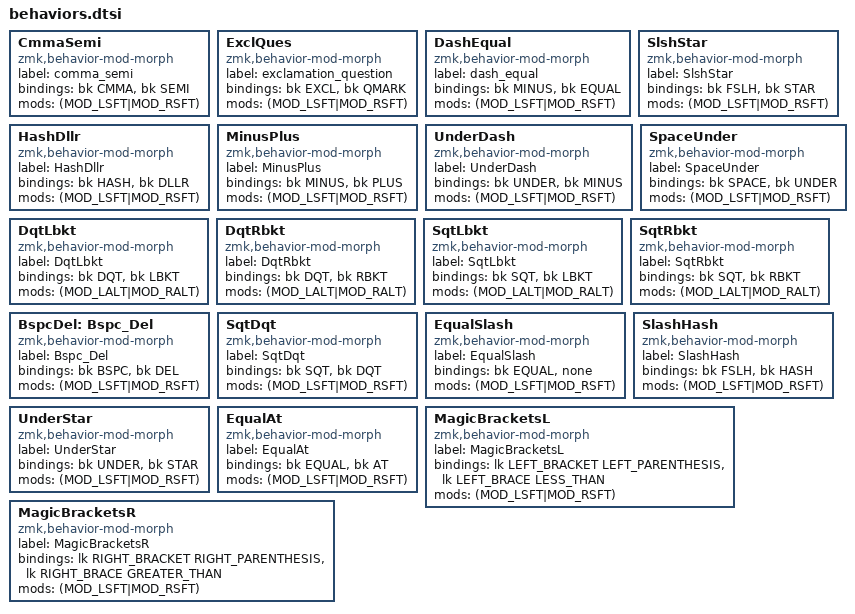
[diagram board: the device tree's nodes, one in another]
CmmaSemi: CmmaSemi {
    compatible = "zmk,behavior-mod-morph";
    label = "comma_semi";
    #binding-cells = <0>;
    bindings = <&bk CMMA>, <&bk SEMI>;
    mods = <(MOD_LSFT|MOD_RSFT)>;
};

ExclQues: ExclQues {
    compatible = "zmk,behavior-mod-morph";
    label = "exclamation_question";
    #binding-cells = <0>;
    bindings = <&bk EXCL>, <&bk QMARK>;
    mods = <(MOD_LSFT|MOD_RSFT)>;
};

DashEqual: DashEqual {
    compatible = "zmk,behavior-mod-morph";
    label = "dash_equal";
    #binding-cells = <0>;
    bindings = <&bk MINUS>, <&bk EQUAL>;
    mods = <(MOD_LSFT|MOD_RSFT)>;
};

SlshStar: SlshStar {
    compatible = "zmk,behavior-mod-morph";
    label = "SlshStar";
    #binding-cells = <0>;
    bindings = <&bk FSLH>, <&bk STAR>;
    mods = <(MOD_LSFT|MOD_RSFT)>;
};
HashDllr: HashDllr {
    compatible = "zmk,behavior-mod-morph";
    label = "HashDllr";
    #binding-cells = <0>;
    bindings = <&bk HASH>, <&bk DLLR>;
    mods = <(MOD_LSFT|MOD_RSFT)>;
};
MinusPlus: MinusPlus {
    compatible = "zmk,behavior-mod-morph";
    label = "MinusPlus";
    #binding-cells = <0>;
    bindings = <&bk MINUS>, <&bk PLUS>;
    mods = <(MOD_LSFT|MOD_RSFT)>;
};
UnderDash: UnderDash {
    compatible = "zmk,behavior-mod-morph";
    label = "UnderDash";
    #binding-cells = <0>;
    bindings = <&bk UNDER>, <&bk MINUS>;
    mods = <(MOD_LSFT|MOD_RSFT)>;
};
SpaceUnder: SpaceUnder {
    compatible = "zmk,behavior-mod-morph";
    label = "SpaceUnder";
    #binding-cells = <0>;
    bindings = <&bk SPACE>, <&bk UNDER>;
    mods = <(MOD_LSFT|MOD_RSFT)>;
};
DqtLbkt: DqtLbkt {
    compatible = "zmk,behavior-mod-morph";
    label = "DqtLbkt";
    #binding-cells = <0>;
    bindings = <&bk DQT>, <&bk LBKT>;
    mods = <(MOD_LALT|MOD_RALT)>;
};
DqtRbkt: DqtRbkt {
    compatible = "zmk,behavior-mod-morph";
    label = "DqtRbkt";
    #binding-cells = <0>;
    bindings = <&bk DQT>, <&bk RBKT>;
    mods = <(MOD_LALT|MOD_RALT)>;
};
SqtLbkt: SqtLbkt {
    compatible = "zmk,behavior-mod-morph";
    label = "SqtLbkt";
    #binding-cells = <0>;
    bindings = <&bk SQT>, <&bk LBKT>;
    mods = <(MOD_LALT|MOD_RALT)>;
};
SqtRbkt: SqtRbkt {
    compatible = "zmk,behavior-mod-morph";
    label = "SqtRbkt";
    #binding-cells = <0>;
    bindings = <&bk SQT>, <&bk RBKT>;
    mods = <(MOD_LALT|MOD_RALT)>;
};
BspcDel: Bspc_Del {
    compatible = "zmk,behavior-mod-morph";
    label = "Bspc_Del";
    #binding-cells = <0>;
    bindings = <&bk BSPC>, <&bk DEL>;
    mods = <(MOD_LSFT|MOD_RSFT)>;
};
SqtDqt: SqtDqt {
    compatible = "zmk,behavior-mod-morph";
    label = "SqtDqt";
    #binding-cells = <0>;
    bindings = <&bk SQT>, <&bk DQT>;
    mods = <(MOD_LSFT|MOD_RSFT)>;
};
EqualSlash: EqualSlash {
    compatible = "zmk,behavior-mod-morph";
    label = "EqualSlash";
    #binding-cells = <0>;
    bindings = <&bk EQUAL>, <&none>; // Disabling shifted behavior for now, to make sure I don't use it and weaken the muscle memory on the new position.
    mods = <(MOD_LSFT|MOD_RSFT)>;
};
SlashHash: SlashHash {
    compatible = "zmk,behavior-mod-morph";
    label = "SlashHash";
    #binding-cells = <0>;
    bindings = <&bk FSLH>, <&bk HASH>;
    mods = <(MOD_LSFT|MOD_RSFT)>;
};
UnderStar: UnderStar {
    compatible = "zmk,behavior-mod-morph";
    label = "UnderStar";
    #binding-cells = <0>;
    bindings = <&bk UNDER>, <&bk STAR>;
    mods = <(MOD_LSFT|MOD_RSFT)>;
};
EqualAt: EqualAt {
    compatible = "zmk,behavior-mod-morph";
    label = "EqualAt";
    #binding-cells = <0>;
    bindings = <&bk EQUAL>, <&bk AT>;
    mods = <(MOD_LSFT|MOD_RSFT)>;
};


/*
Magic Brackets Behavior

S L => Output (L = Linger, S = Shifted)
-------------
_ _ => (
_ X => [
X _ => {
X X => <

*/
MagicBracketsL: MagicBracketsL {
    compatible = "zmk,behavior-mod-morph";
    label = "MagicBracketsL";
    #binding-cells = <0>;
    bindings = <&lk LEFT_BRACKET LEFT_PARENTHESIS>, <&lk LEFT_BRACE LESS_THAN>;
    mods = <(MOD_LSFT|MOD_RSFT)>;
};

MagicBracketsR: MagicBracketsR {
    compatible = "zmk,behavior-mod-morph";
    label = "MagicBracketsR";
    #binding-cells = <0>;
    bindings = <&lk RIGHT_BRACKET RIGHT_PARENTHESIS>, <&lk RIGHT_BRACE GREATER_THAN>;
    mods = <(MOD_LSFT|MOD_RSFT)>;
};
